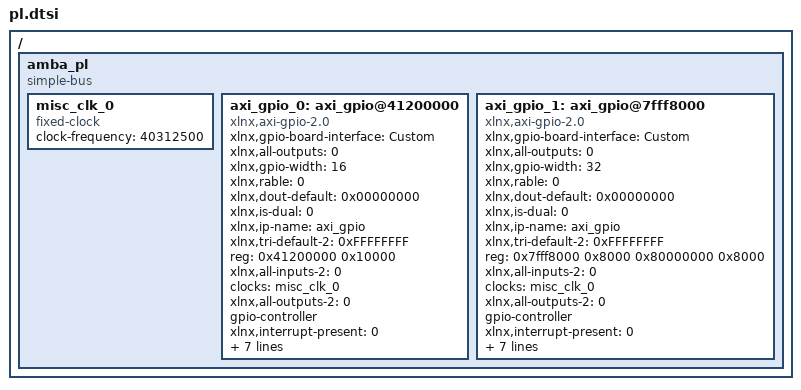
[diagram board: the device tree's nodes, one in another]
/ {
	amba_pl: amba_pl {
		ranges;
		compatible = "simple-bus";
		#address-cells = <1>;
		#size-cells = <1>;
		misc_clk_0: misc_clk_0 {
			compatible = "fixed-clock";
			clock-frequency = <40312500>;
			#clock-cells = <0>;
		};
		axi_gpio_0: axi_gpio@41200000 {
			xlnx,gpio-board-interface = "Custom";
			compatible = "xlnx,axi-gpio-2.0" , "xlnx,xps-gpio-1.00.a";
			xlnx,all-outputs = <0>;
			#gpio-cells = <2>;
			xlnx,gpio-width = <16>;
			xlnx,rable = <0>;
			xlnx,dout-default = <0x00000000>;
			xlnx,is-dual = <0>;
			xlnx,ip-name = "axi_gpio";
			xlnx,tri-default-2 = <0xFFFFFFFF>;
			reg = <0x41200000 0x10000>;
			xlnx,all-inputs-2 = <0>;
			clocks = <&misc_clk_0>;
			xlnx,all-outputs-2 = <0>;
			gpio-controller;
			xlnx,interrupt-present = <0>;
			xlnx,gpio2-board-interface = "Custom";
			xlnx,edk-iptype = "PERIPHERAL";
			xlnx,dout-default-2 = <0x00000000>;
			xlnx,gpio2-width = <32>;
			status = "okay";
			clock-names = "s_axi_aclk";
			xlnx,tri-default = <0xFFFFFFFF>;
			xlnx,name = "axi_gpio_0";
			xlnx,all-inputs = <1>;
		};
		axi_gpio_1: axi_gpio@7fff8000 {
			xlnx,gpio-board-interface = "Custom";
			compatible = "xlnx,axi-gpio-2.0" , "xlnx,xps-gpio-1.00.a";
			xlnx,all-outputs = <0>;
			#gpio-cells = <2>;
			xlnx,gpio-width = <32>;
			xlnx,rable = <0>;
			xlnx,dout-default = <0x00000000>;
			xlnx,is-dual = <0>;
			xlnx,ip-name = "axi_gpio";
			xlnx,tri-default-2 = <0xFFFFFFFF>;
			reg = <0x7fff8000 0x8000 0x80000000 0x8000>;
			xlnx,all-inputs-2 = <0>;
			clocks = <&misc_clk_0>;
			xlnx,all-outputs-2 = <0>;
			gpio-controller;
			xlnx,interrupt-present = <0>;
			xlnx,gpio2-board-interface = "Custom";
			xlnx,edk-iptype = "PERIPHERAL";
			xlnx,dout-default-2 = <0x00000000>;
			xlnx,gpio2-width = <32>;
			status = "okay";
			clock-names = "s_axi_aclk";
			xlnx,tri-default = <0xFFFFFFFF>;
			xlnx,name = "axi_gpio_1";
			xlnx,all-inputs = <1>;
		};
	};
};
